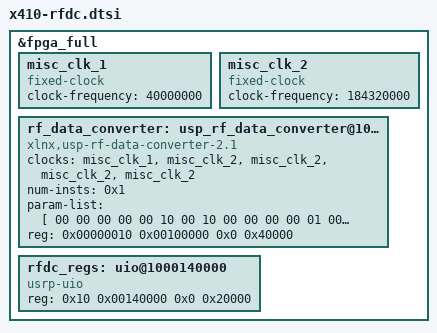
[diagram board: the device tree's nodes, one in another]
/*
 * Copyright 2021 Ettus Research, a National Instruments Brand
 *
 * SPDX-License-Identifier: LGPL-3.0-or-later
 */

&fpga_full {
	#address-cells = <2>;
	#size-cells = <2>;

	misc_clk_1: misc_clk_1 {
		#clock-cells = <0>;
		clock-frequency = <40000000>;
		compatible = "fixed-clock";
	};

	misc_clk_2: misc_clk_2 {
		#clock-cells = <0>;
		clock-frequency = <184320000>;
		compatible = "fixed-clock";
	};

	rf_data_converter: usp_rf_data_converter@1000100000 {
		clock-names = "s_axi_aclk", "m0_axis_aclk", "m2_axis_aclk", "s0_axis_aclk", "s1_axis_aclk";
		clocks = <&misc_clk_1>, <&misc_clk_2>, <&misc_clk_2>, <&misc_clk_2>, <&misc_clk_2>;
		compatible = "xlnx,usp-rf-data-converter-2.1";
		num-insts = <0x1>;
		param-list = [ 00 00 00 00 00 10 00 10 00 00 00 00 01 00 00 00 00 00 00 00 00 00 00 00 01 00 00 00 01 00 00 00 00 00 00 00 01 00 00 00 00 00 00 00 0f d6 ff 39 cc 97 07 40 0a d7 a3 70 3d 0a a7 40 0a d7 a3 70 3d 0a 67 40 0a 00 00 00 02 00 00 00 01 00 00 00 00 00 00 00 9e ef a7 c6 4b 37 1a 40 04 00 00 00 01 00 00 00 00 00 00 00 00 00 00 00 00 00 00 00 01 00 00 00 00 00 00 00 00 00 00 00 00 00 00 00 00 00 00 00 00 00 00 00 02 00 00 00 00 00 00 00 00 00 00 00 00 00 00 00 02 00 00 00 00 00 00 00 00 00 00 00 10 00 00 00 02 00 00 00 00 00 00 00 00 00 00 00 02 00 00 00 00 00 00 00 10 00 00 00 02 00 00 00 00 00 00 00 00 00 00 00 02 00 00 00 00 00 00 00 10 00 00 00 00 00 00 00 00 00 00 00 00 00 00 00 03 00 00 00 00 00 00 00 10 00 00 00 00 00 00 00 00 00 00 00 00 00 00 00 03 00 00 00 01 00 00 00 00 00 00 00 0f d6 ff 39 cc 97 07 40 0a d7 a3 70 3d 0a a7 40 0a d7 a3 70 3d 0a 67 40 0a 00 00 00 02 00 00 00 01 00 00 00 00 00 00 00 9e ef a7 c6 4b 37 1a 40 04 00 00 00 01 00 00 00 00 00 00 00 00 00 00 00 00 00 00 00 01 00 00 00 00 00 00 00 00 00 00 00 00 00 00 00 00 00 00 00 00 00 00 00 02 00 00 00 00 00 00 00 00 00 00 00 00 00 00 00 02 00 00 00 00 00 00 00 00 00 00 00 10 00 00 00 02 00 00 00 00 00 00 00 00 00 00 00 02 00 00 00 00 00 00 00 10 00 00 00 02 00 00 00 00 00 00 00 00 00 00 00 02 00 00 00 00 00 00 00 10 00 00 00 00 00 00 00 00 00 00 00 00 00 00 00 03 00 00 00 00 00 00 00 10 00 00 00 00 00 00 00 00 00 00 00 00 00 00 00 03 00 00 00 00 00 00 00 00 00 00 00 9a 99 99 99 99 99 19 40 00 00 00 00 00 00 b9 40 00 00 00 00 00 00 00 00 0a 00 00 00 02 00 00 00 01 00 00 00 00 00 00 00 9e ef a7 c6 4b 37 1a 40 00 00 00 00 00 00 00 00 00 00 00 00 02 00 00 00 00 00 00 00 00 00 00 00 00 00 00 00 02 00 00 00 00 00 00 00 00 00 00 00 00 00 00 00 02 00 00 00 00 00 00 00 00 00 00 00 00 00 00 00 02 00 00 00 00 00 00 00 00 00 00 00 10 00 00 00 00 00 00 00 00 00 00 00 00 00 00 00 03 00 00 00 00 00 00 00 10 00 00 00 00 00 00 00 00 00 00 00 00 00 00 00 03 00 00 00 00 00 00 00 10 00 00 00 00 00 00 00 00 00 00 00 00 00 00 00 03 00 00 00 00 00 00 00 10 00 00 00 00 00 00 00 00 00 00 00 00 00 00 00 03 00 00 00 00 00 00 00 00 00 00 00 9a 99 99 99 99 99 19 40 00 00 00 00 00 00 b9 40 00 00 00 00 00 00 00 00 0a 00 00 00 02 00 00 00 01 00 00 00 00 00 00 00 9e ef a7 c6 4b 37 1a 40 00 00 00 00 00 00 00 00 00 00 00 00 02 00 00 00 00 00 00 00 00 00 00 00 00 00 00 00 02 00 00 00 00 00 00 00 00 00 00 00 00 00 00 00 02 00 00 00 00 00 00 00 00 00 00 00 00 00 00 00 02 00 00 00 00 00 00 00 00 00 00 00 10 00 00 00 00 00 00 00 00 00 00 00 00 00 00 00 03 00 00 00 00 00 00 00 10 00 00 00 00 00 00 00 00 00 00 00 00 00 00 00 03 00 00 00 00 00 00 00 10 00 00 00 00 00 00 00 00 00 00 00 00 00 00 00 03 00 00 00 00 00 00 00 10 00 00 00 00 00 00 00 00 00 00 00 00 00 00 00 03 00 00 00 01 00 00 00 00 00 00 00 0f d6 ff 39 cc 97 07 40 0a d7 a3 70 3d 0a a7 40 0a d7 a3 70 3d 0a 67 40 0a 00 00 00 02 00 00 00 01 00 00 00 00 00 00 00 fc a9 f1 d2 4d 62 10 40 02 00 00 00 01 00 00 00 00 00 00 00 01 00 00 00 00 00 00 00 01 00 00 00 00 00 00 00 01 00 00 00 00 00 00 00 01 00 00 00 08 00 00 00 02 00 00 00 00 00 00 00 02 00 00 00 01 00 00 00 08 00 00 00 02 00 00 00 00 00 00 00 02 00 00 00 01 00 00 00 08 00 00 00 02 00 00 00 00 00 00 00 02 00 00 00 01 00 00 00 08 00 00 00 02 00 00 00 00 00 00 00 02 00 00 00 00 00 00 00 00 00 00 00 00 00 00 00 00 00 00 40 00 00 00 00 00 40 9f 40 00 00 00 00 00 00 00 00 0a 00 00 00 02 00 00 00 01 00 00 00 00 00 00 00 fc a9 f1 d2 4d 62 10 40 02 00 00 00 00 00 00 00 02 00 00 00 00 00 00 00 02 00 00 00 00 00 00 00 02 00 00 00 00 00 00 00 02 00 00 00 00 00 00 00 08 00 00 00 00 00 00 00 00 00 00 00 03 00 00 00 00 00 00 00 08 00 00 00 00 00 00 00 00 00 00 00 03 00 00 00 00 00 00 00 08 00 00 00 00 00 00 00 00 00 00 00 03 00 00 00 00 00 00 00 08 00 00 00 00 00 00 00 00 00 00 00 03 00 00 00 01 00 00 00 00 00 00 00 0f d6 ff 39 cc 97 07 40 0a d7 a3 70 3d 0a a7 40 0a d7 a3 70 3d 0a 67 40 0a 00 00 00 02 00 00 00 01 00 00 00 00 00 00 00 fc a9 f1 d2 4d 62 10 40 02 00 00 00 01 00 00 00 00 00 00 00 01 00 00 00 00 00 00 00 01 00 00 00 00 00 00 00 01 00 00 00 00 00 00 00 01 00 00 00 08 00 00 00 02 00 00 00 00 00 00 00 02 00 00 00 01 00 00 00 08 00 00 00 02 00 00 00 00 00 00 00 02 00 00 00 01 00 00 00 08 00 00 00 02 00 00 00 00 00 00 00 02 00 00 00 01 00 00 00 08 00 00 00 02 00 00 00 00 00 00 00 02 00 00 00 00 00 00 00 00 00 00 00 00 00 00 00 00 00 00 40 00 00 00 00 00 40 9f 40 00 00 00 00 00 00 00 00 0a 00 00 00 02 00 00 00 01 00 00 00 00 00 00 00 fc a9 f1 d2 4d 62 10 40 02 00 00 00 00 00 00 00 02 00 00 00 00 00 00 00 02 00 00 00 00 00 00 00 02 00 00 00 00 00 00 00 02 00 00 00 00 00 00 00 08 00 00 00 00 00 00 00 00 00 00 00 03 00 00 00 00 00 00 00 08 00 00 00 00 00 00 00 00 00 00 00 03 00 00 00 00 00 00 00 08 00 00 00 00 00 00 00 00 00 00 00 03 00 00 00 00 00 00 00 08 00 00 00 00 00 00 00 00 00 00 00 03 00 00 00];
		reg = <0x00000010 0x00100000 0x0 0x40000>;
	};

	rfdc_regs: uio@1000140000 {
		status = "okay";
		compatible = "usrp-uio";
		reg = <0x10 0x00140000 0x0 0x20000>;
		reg-names = "rfdc-regs";
	};
};
